# N32H474 register map
Vendor: Nationstech Ltd.; File version: 1.0
Registers are 32-bit, read-write, reset 0x0 unless marked. A register's access mark holds for its fields unless they carry their own. Offsets are from the block's base; [hi:lo] are bit positions; {n}, {i} and the like mark numbered series; 'fields as' and 'values as' point back to an identical list.

## I2S2_EXT — Inter—IC Sound
Base 0x40002600
Same registers: I2S3_EXT 0x40002A00
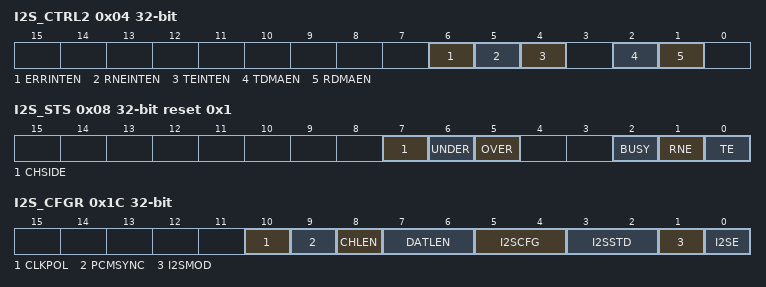
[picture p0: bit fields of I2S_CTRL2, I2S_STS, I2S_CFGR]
0x04 I2S_CTRL2
  [6] ERRINTEN, [5] RNEINTEN, [4] TEINTEN, [2] TDMAEN, [1] RDMAEN
0x08 I2S_STS reset 0x1
  [7] CHSIDE, [6] UNDER, [5] OVER, [2] BUSY, [1] RNE, [0] TE
0x0C I2S_DAT
  [15:0] DAT
0x1C I2S_CFGR
  [10] CLKPOL, [9] PCMSYNC, [8] CHLEN, [7:6] DATLEN, [5:4] I2SCFG, [3:2] I2SSTD, [1] I2SMOD, [0] I2SE

## DMA1 — Direct memory access controller
Base 0x40020000
Same registers: DMA2 0x40020400
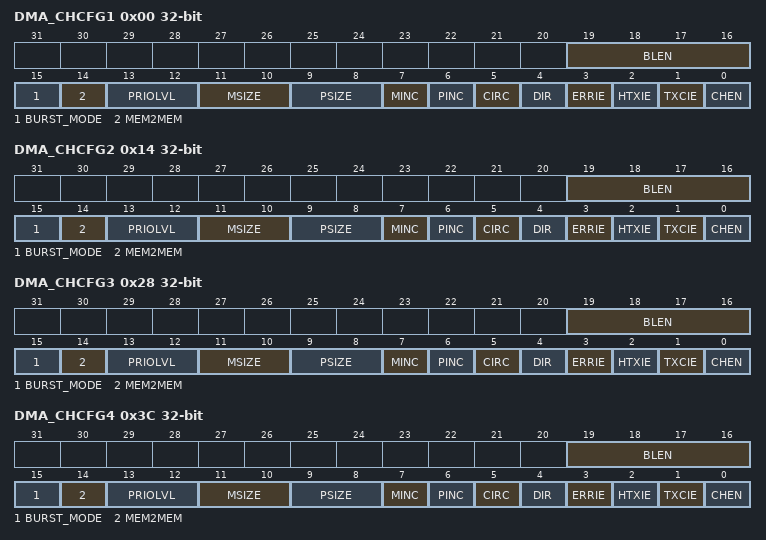
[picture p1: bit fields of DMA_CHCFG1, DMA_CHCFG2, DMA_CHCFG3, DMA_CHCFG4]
0x00 DMA_CHCFG1
  [19:16] BLEN, [15] BURST_MODE, [14] MEM2MEM, [13:12] PRIOLVL, [11:10] MSIZE, [9:8] PSIZE, [7] MINC, [6] PINC, [5] CIRC, [4] DIR, [3] ERRIE, [2] HTXIE, [1] TXCIE, [0] CHEN
0x04 DMA_MADDR1
  [31:0] ADDR
0x08 DMA_PADDR1
  [31:0] ADDR
0x0C DMA_CHSEL1
  [7:0] CH_SEL
0x10 DMA_TXNUM1
  [15:0] NDTX
0x14 DMA_CHCFG2
  fields as DMA_CHCFG1
0x18 DMA_MADDR2
  [31:0] ADDR
0x1C DMA_PADDR2
  [31:0] ADDR
0x20 DMA_CHSEL2
  [7:0] CH_SEL
0x24 DMA_TXNUM2
  [15:0] NDTX
0x28 DMA_CHCFG3
  fields as DMA_CHCFG1
0x2C DMA_MADDR3
  [31:0] ADDR
0x30 DMA_PADDR3
  [31:0] ADDR
0x34 DMA_CHSEL3
  [7:0] CH_SEL
0x38 DMA_TXNUM3
  [15:0] NDTX
0x3C DMA_CHCFG4
  fields as DMA_CHCFG1
0x40 DMA_MADDR4
  [31:0] ADDR
0x44 DMA_PADDR4
  [31:0] ADDR
0x48 DMA_CHSEL4
  [7:0] CH_SEL
0x4C DMA_TXNUM4
  [15:0] NDTX
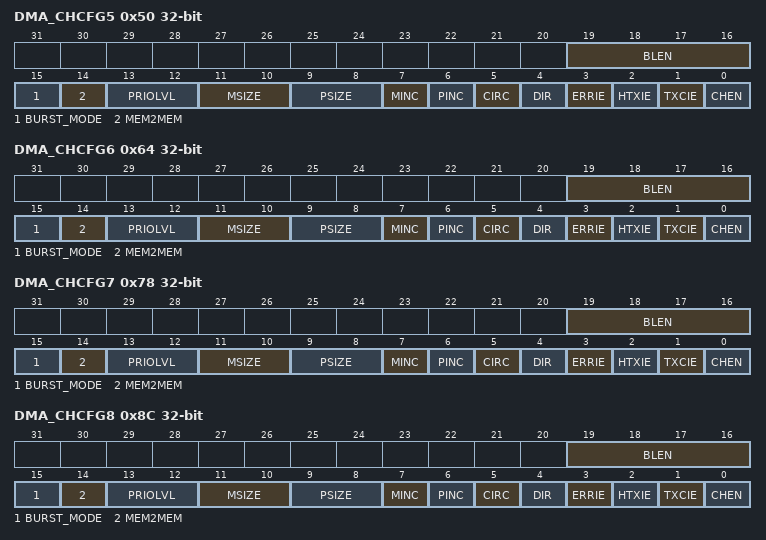
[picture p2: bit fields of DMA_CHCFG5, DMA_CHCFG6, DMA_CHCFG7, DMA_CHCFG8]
0x50 DMA_CHCFG5
  fields as DMA_CHCFG1
0x54 DMA_MADDR5
  [31:0] ADDR
0x58 DMA_PADDR5
  [31:0] ADDR
0x5C DMA_CHSEL5
  [7:0] CH_SEL
0x60 DMA_TXNUM5
  [15:0] NDTX
0x64 DMA_CHCFG6
  fields as DMA_CHCFG1
0x68 DMA_MADDR6
  [31:0] ADDR
0x6C DMA_PADDR6
  [31:0] ADDR
0x70 DMA_CHSEL6
  [7:0] CH_SEL
0x74 DMA_TXNUM6
  [15:0] NDTX
0x78 DMA_CHCFG7
  fields as DMA_CHCFG1
0x7C DMA_MADDR7
  [31:0] ADDR
0x80 DMA_PADDR7
  [31:0] ADDR
0x84 DMA_CHSEL7
  [7:0] CH_SEL
0x88 DMA_TXNUM7
  [15:0] NDTX
0x8C DMA_CHCFG8
  fields as DMA_CHCFG1
0x90 DMA_MADDR8
  [31:0] ADDR
0x94 DMA_PADDR8
  [31:0] ADDR
0x98 DMA_CHSEL8
  [7:0] CH_SEL
0x9C DMA_TXNUM8
  [15:0] NDTX
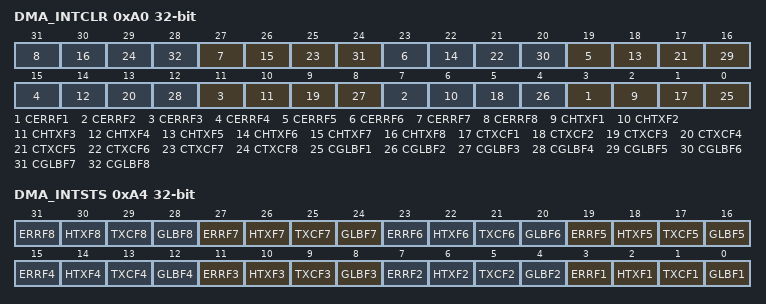
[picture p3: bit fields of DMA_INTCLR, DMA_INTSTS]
0xA0 DMA_INTCLR
  [4n-1] CERRF{n} (n=1..8), [4n-2] CHTXF{n} (n=1..8), [4n-3] CTXCF{n} (n=1..8), [4n-4] CGLBF{n} (n=1..8)
0xA4 DMA_INTSTS ro
  [4n-1] ERRF{n} (n=1..8), [4n-2] HTXF{n} (n=1..8), [4n-3] TXCF{n} (n=1..8), [4n-4] GLBF{n} (n=1..8)
0xA8 DMA_BURSTEN reset 0x1
  [0] BURST_BYPASS

## LPTIM1
Base 0x40006C00
Same registers: LPTIM2 0x40007000
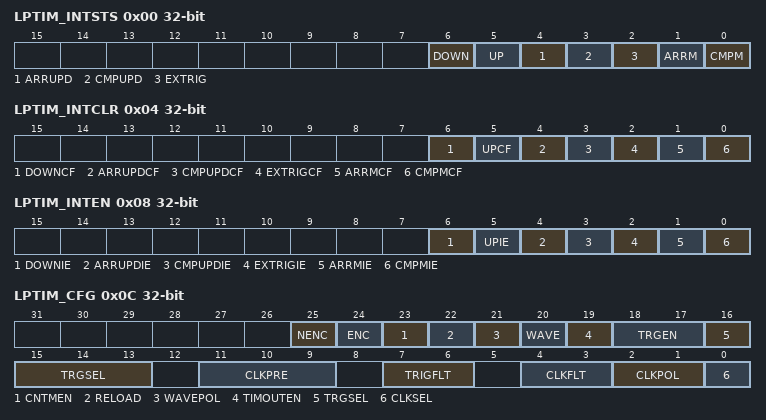
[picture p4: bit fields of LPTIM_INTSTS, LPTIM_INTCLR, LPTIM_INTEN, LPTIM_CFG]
0x00 LPTIM_INTSTS
  [6] DOWN, [5] UP, [4] ARRUPD, [3] CMPUPD, [2] EXTRIG, [1] ARRM, [0] CMPM
0x04 LPTIM_INTCLR
  [6] DOWNCF, [5] UPCF, [4] ARRUPDCF, [3] CMPUPDCF, [2] EXTRIGCF, [1] ARRMCF, [0] CMPMCF
0x08 LPTIM_INTEN
  [6] DOWNIE, [5] UPIE, [4] ARRUPDIE, [3] CMPUPDIE, [2] EXTRIGIE, [1] ARRMIE, [0] CMPMIE
0x0C LPTIM_CFG
  [25] NENC, [24] ENC, [23] CNTMEN, [22] RELOAD, [21] WAVEPOL, [20] WAVE, [19] TIMOUTEN, [18:17] TRGEN, [16:13] TRGSEL, [11:9] CLKPRE, [7:6] TRIGFLT, [4:3] CLKFLT, [2:1] CLKPOL, [0] CLKSEL
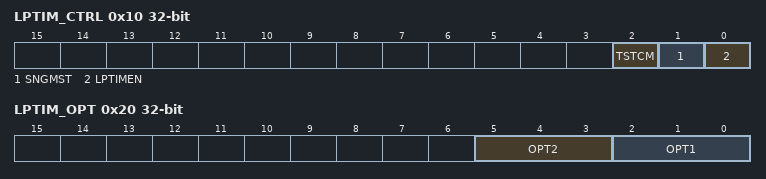
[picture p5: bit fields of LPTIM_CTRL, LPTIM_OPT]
0x10 LPTIM_CTRL
  [2] TSTCM, [1] SNGMST, [0] LPTIMEN
0x14 LPTIM_CMP
  [15:0] CMPVAL
0x18 LPTIM_ARR reset 0x1
  [15:0] ARRVAL
0x1C LPTIM_CNT
  [15:0] CNTVAL
0x20 LPTIM_OPT
  [5:3] OPT2, [2:0] OPT1

## SHRTIM_Master — Super high resolution timer: Master Timers
Base 0x40030000
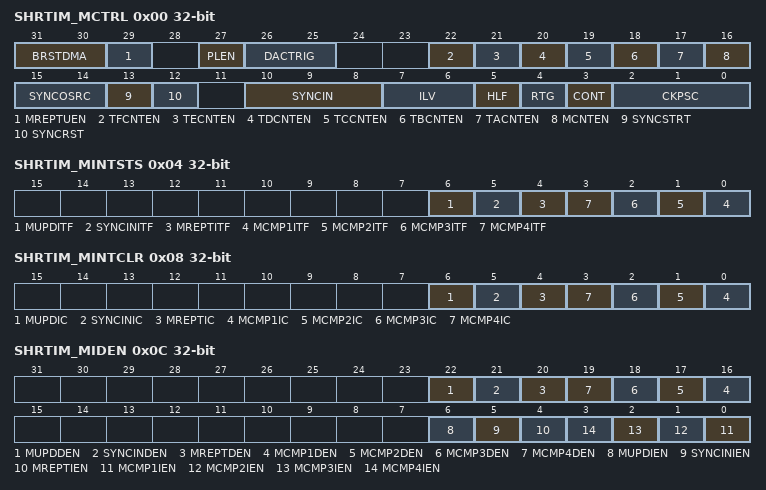
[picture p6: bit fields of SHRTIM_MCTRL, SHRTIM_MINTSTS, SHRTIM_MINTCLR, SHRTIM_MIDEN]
0x00 SHRTIM_MCTRL — SHRTIM configuration register for master timer
  [31:30] BRSTDMA, [29] MREPTUEN, [27] PLEN, [26:25] DACTRIG, [22] TFCNTEN, [21] TECNTEN, [20] TDCNTEN, [19] TCCNTEN, [18] TBCNTEN, [17] TACNTEN, [16] MCNTEN, [15:14] SYNCOSRC, [13] SYNCSTRT, [12] SYNCRST, [10:8] SYNCIN, [7:6] ILV, [5] HLF, [4] RTG, [3] CONT, [2:0] CKPSC
0x04 SHRTIM_MINTSTS ro — SHRTIM status register for master timer interrupt
  [6] MUPDITF, [5] SYNCINITF, [4] MREPTITF, [n-1] MCMP{n}ITF (n=1..4)
0x08 SHRTIM_MINTCLR wo — SHRTIM master timer interrupt clear register
  [6] MUPDIC, [5] SYNCINIC, [4] MREPTIC, [n-1] MCMP{n}IC (n=1..4)
0x0C SHRTIM_MIDEN — SHRTIM master timer interrupt and DMA request enable register
  [22] MUPDDEN, [21] SYNCINDEN, [20] MREPTDEN, [n+15] MCMP{n}DEN (n=1..4), [6] MUPDIEN, [5] SYNCINIEN, [4] MREPTIEN, [n-1] MCMP{n}IEN (n=1..4)
0x10 SHRTIM_MCNT — SHRTIM master timer counter register
  [15:0] MCOUNT
0x14 SHRTIM_MPRD reset 0xFFDF — SHRTIM master timer period register
  [15:0] MPRD
0x18 SHRTIM_MREPT — SHRTIM master timer repetition register
  [7:0] MREPT
0x1C SHRTIM_MCMP1DAT — SHRTIM master timer compare 1 register
  [15:0] MCMP1DAT
{0x1C+4i} SHRTIM_MCMP{i}DAT (i=2..4) — SHRTIM master timer compare {i} register
  [15:0] MCMP{i}DAT
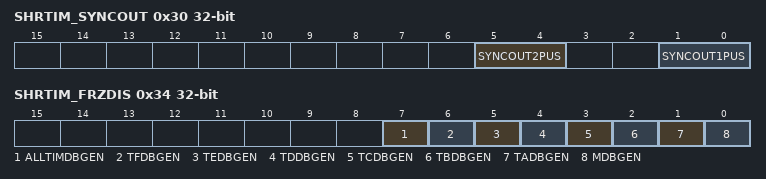
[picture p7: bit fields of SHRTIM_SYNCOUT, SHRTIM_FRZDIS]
0x30 SHRTIM_SYNCOUT — SYNOUT configure register
  [5:4] SYNCOUT2PUS, [1:0] SYNCOUT1PUS
0x34 SHRTIM_FRZDIS — Timer behavior during CPU freeze
  [7] ALLTIMDBGEN, [6] TFDBGEN, [5] TEDBGEN, [4] TDDBGEN, [3] TCDBGEN, [2] TBDBGEN, [1] TADBGEN, [0] MDBGEN

## USB_FS — Universal serial bus full-speed device interface
Base 0x40004800
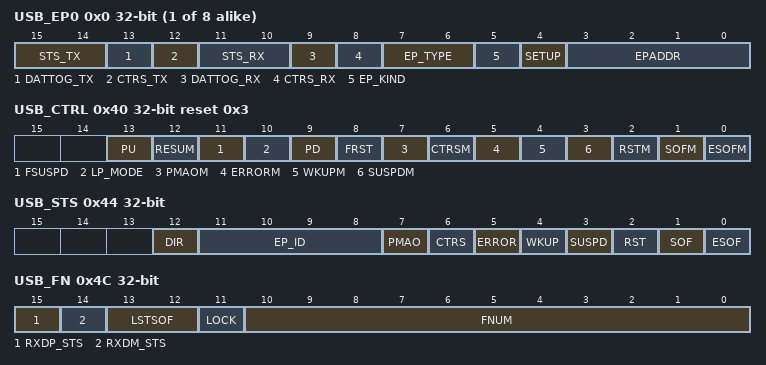
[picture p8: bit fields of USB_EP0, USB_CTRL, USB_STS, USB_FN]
{0x0+4i} USB_EP{i} (i=0..7)
  [15:14] STS_TX, [13] DATTOG_TX, [12] CTRS_TX, [11:10] STS_RX, [9] DATTOG_RX, [8] CTRS_RX, [7:6] EP_TYPE, [5] EP_KIND, [4] SETUP, [3:0] EPADDR
0x40 USB_CTRL reset 0x3 (reset mask 0xFF1F)
  [13] PU, [12] RESUM, [11] FSUSPD, [10] LP_MODE, [9] PD, [8] FRST, [7] PMAOM, [6] CTRSM, [5] ERRORM, [4] WKUPM, [3] SUSPDM, [2] RSTM, [1] SOFM, [0] ESOFM
0x44 USB_STS (reset mask 0xFF1F)
  [12] DIR, [11:8] EP_ID, [7] PMAO, [6] CTRS, [5] ERROR, [4] WKUP, [3] SUSPD, [2] RST, [1] SOF, [0] ESOF
0x48 USB_BUFTAB
  [15:3] BUFTAB
0x4C USB_FN
  [15] RXDP_STS, [14] RXDM_STS, [13:12] LSTSOF, [11] LOCK, [10:0] FNUM
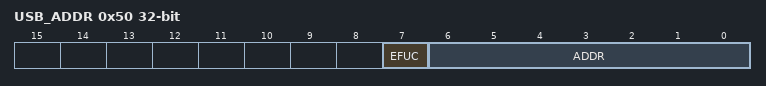
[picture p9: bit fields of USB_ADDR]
0x50 USB_ADDR (reset mask 0x7F)
  [7] EFUC, [6:0] ADDR
